# WBZ450 register map
Vendor: Microchip
Registers are 32-bit, read-write, reset 0x0 unless marked. A register's access mark holds for its fields unless they carry their own. Addresses are absolute, and some are shared; only a register's first bit layout is shown; [hi:lo] are bit positions; {n}, {i} and the like mark numbered series; 'fields as' and 'values as' point back to an identical list.

## ADCHS
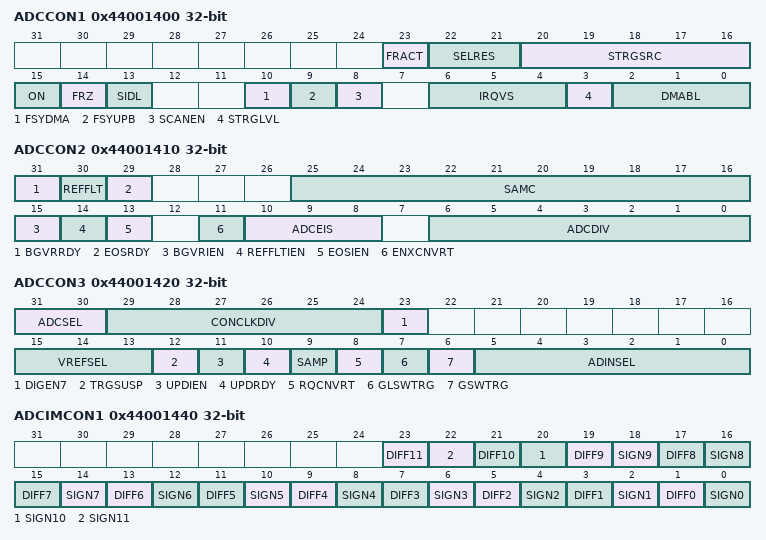
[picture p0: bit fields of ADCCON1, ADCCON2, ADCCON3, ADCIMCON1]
0x44001400 ADCCON1
  [23] FRACT — Fractional Data Output Format bit
    1=FRAC (Fractional); 0=INT (Integer)
  [22:21] SELRES — Shared ADC7 Resolution bits
    3=12_BITS (12 bits (default)); 2=10_BITS; 1=8_BITS; 0=6_BITS
  [20:16] STRGSRC — Scan Trigger Source Select bits
    31=EXT_TRIG_VAL (External trigger for validation); {v}=EVSYS_{v+31} (ADC_TRIG_{v}) (v=5..16); 4=INT0; 2=SW_LVL (Software level trigger); 1=SW_EDGE (Software edge trigger); 0=NONE (No Trigger)
  [15] ON — ADC Module Enable bit
    1=ENABLED (ADC module is enabled); 0=DISABLED (ADC module is disabled)
  [14] FRZ
  [13] SIDL — Stop in Idle Mode bit
    1=DISCONTINUE (Discontinue module operation when device enters Idle mode); 0=CONTINUE (Continue module operation in Idle mode)
  [10] FSYDMA
  [9] FSYUPB
  [8] SCANEN
  [6:4] IRQVS — Interrupt Vector Shift bits
    {v}=SHL_{v} (Shift x left {v} bit position) (v=0..7)
  [3] STRGLVL — Scan Trigger High Level/Positive Edge Sensitivity bit
    1=SCTRIG_HIGH (Scan trigger is high level sensitive. Once STRIG mode is selected the scan trigger will continue for all selected analog inputs); 0=SCTRIG_POSEDGE (Scan trigger is positive edge sensitive. Once STRIG mode is selected only a single scan trigger will be generated which will complete the scan of all selected analog inputs. (TRGSRCx in the ADCTRGx register))
  [2:0] DMABL — DMA to System RAM Buffer Length Size bits
    7=128_DMABL (Allocates 128 locations in system memory to each analog input); 6=64_DMABL (Allocates 64 locations in system memory to each analog input); 5=32_DMABL (Allocates 32 locations in system memory to each analog input); 4=16_DMABL (Allocates 16 locations in system memory to each analog input); 3=8_DMABL (Allocates 8 locations in system memory to each analog input); 2=4_DMABL (Allocates 4 locations in system memory to each analog input); 1=2_DMABL (Allocates 2 locations in system memory to each analog input); 0=1_DMABL (Allocates 1 location in system memory to each analog input)
{0x440013F4+0x10*i} ADCCON{i}CLR (i=1..3)
{0x440013F8+0x10*i} ADCCON{i}SET (i=1..3)
{0x440013FC+0x10*i} ADCCON{i}INV (i=1..3)
0x44001410 ADCCON2
  [31] BGVRRDY — Band Gap Voltage/ADC Reference Voltage Status bit
    1=VREF_RDY (Both band gap voltage and ADC reference voltages (Vref) are ready); 0=VREF_NOTRDY (Either or both band gap voltage and ADC reference voltages (Vref) are not ready)
  [30] REFFLT — Band Gap/ Vref / AVdd BOR Fault Status bit
    1=BG_VREF_FLT (Fault in band gap or the Vref voltage while the ON bit (ADCCON1) was set. Most likely a band gap or Vref fault will be caused by a BOR of the analog Vdd supply.); 0=BG_VREF_OK (Band gap and Vref voltage are working properly)
  [29] EOSRDY — End of Scan Interrupt Status bit
    1=SCAN_COMPLETE (All analog inputs are considered for scanning through the scan trigger (all analog inputs specified in the ADCCSS1 and ADCCSS2 registers) have completed scanning); 0=SCAN_NOT_COMPLETE (Scanning has not completed)
  [25:16] SAMC — Sample Time for the Shared ADC (ADC7) bits
  [15] BGVRIEN — Band Gap/ Vref Voltage Ready Interrupt Enable bit
    1=BGVRDDY_INT (Interrupt will be generated when the BGVRDDY bit is set); 0=NOBGVRDDY_INT (No interrupt is generated when the BGVRRDY bit is set)
  [14] REFFLTIEN — Band Gap/ Vref Voltage Fault Interrupt Enable bit
    1=REFFLT_INT (Interrupt will be generated when the REFFLT bit is set); 0=NOREFFLT_INT (No interrupt is generated when the REFFLT bit is set)
  [13] EOSIEN — End of Scan Interrupt Enable bit
    1=EOSRDY_INT (Interrupt will be generated when EOSRDY bit is set); 0=NOEOSRDY_INT (No interrupt is generated when the EOSRDY bit is set)
  [11] ENXCNVRT
  [10:8] ADCEIS — Shared ADC Early Interrupt Select bits
    {v}={v+1}CLKS_EARLY (The data ready interrupt is generated {v+1} ADC clocks prior to end of conversion) (v=2..7); 1=2CLKS_EARLY (The data ready interrupt is generated 2 ADC module clocks prior to end of conversion); 0=1CLKS_EARLY (The data ready interrupt is generated 1 ADC module clock prior to end of conversion)
  [6:0] ADCDIV — Shared ADC Clock Divider bits
0x44001420 ADCCON3
  [31:30] ADCSEL — Analog-to-Digital Clock Source bits
    3=SYSCLK; 2=REFCLK3; 1=FRC; 0=PBCLK1
  [29:24] CONCLKDIV — Analog-to-Digital Control Clock Divider bits
  [23] DIGEN7 — Shared ADC (ADC7) Digital Enable bit
  [15:13] VREFSEL — Voltage Reference Input Selection bits
    0=AVDD_AVSS (ADC VREFH is AVDD, ADC VREFL is AVSS)
  [12] TRGSUSP — Trigger Suspend bit
    1=TRIG_BLOCKED (Triggers are blocked from starting a new analog-to-digital conversion); 0=TRIG_NOT_BLOCKED (Triggers are not blocked)
  [11] UPDIEN — Update Ready Interrupt Enable bit
    1=INT_ON_UPDATE_RDY (Interrupt will be generated when the UPDRDY bit is set by hardware); 0=NO_INT_ON_UPDATE_RDY (No interrupt is generated)
  [10] UPDRDY — ADC Update Ready Status bit
    1=UPDATE_RDY (ADC SFRs can be updated); 0=UPDATE_NOT_RDY (ADC SFRs cannot be updated)
  [9] SAMP — Shared ADC7 Analog Input Sampling Enable bit
    1=SAMPLE (The ADC S&H amplifier is sampling); 0=HOLD (The ADC S&H amplifier is holding)
  [8] RQCNVRT — Individual ADC Input Conversion Request bit
    1=IND_TRIGGER (Trigger the conversion of the selected ADC input as specified by the ADINSEL bits); 0=NO_TRIGGER (Do not trigger the conversion)
  [7] GLSWTRG — Global Level Software Trigger bit
    1=GLSWTRG (Trigger conversion for ADC inputs that have selected the GLSWTRG bit as the trigger signal); 0=NO_GLSWTRG (Do not trigger an analog-to-digital conversion)
  [6] GSWTRG — Global Software Trigger bit
    1=GSWTRG (Trigger conversion for ADC inputs that have selected the GSWTRG bit as either through the associated TRGSRC bits in the ADCTRGx registers or through the STRGSRC<4:0> bits in the ADCCON1 register the trigger signal); 0=NO_GSWTRG (Do not trigger an analog-to-digital conversion)
  [5:0] ADINSEL — Analog Input Select bits
    11=TMP_SENSE (CTMU Temperature Sensor (internal AN11)); 10=VBATDIV2_SENSE (VBAT/2 (internal AN10)); 9=1P2V_SENSE (IVref 1.2V (internal AN9)); 8=BGREF (BandGap Reference (internal AN8)); {v}=AN{v} (v=0..7)
0x44001440 ADCIMCON1
  [23] DIFF11 — AN11 Mode bit
    1=DIFF (Selects AN11 differential input pair as AN11+ and ANN0-); 0=SINGLE (AN11 is using Single-ended mode)
  [2n] SIGN{n} (n=0..11) — AN{n} Signed Data Mode bit
    1=SIGNED (AN{n} is using Signed Data mode); 0=UNSIGNED (AN{n} is using Unsigned Data mode)
  [21] DIFF10 — AN10 Mode bit
    1=DIFF (Selects AN10 differential input pair as AN10+ and ANN0-); 0=SINGLE (AN10 is using Single-ended mode)
  [19] DIFF9 — AN9 Mode bit
    1=DIFF (Selects AN9 differential input pair as AN9+ and ANN0-); 0=SINGLE (AN9 is using Single-ended mode)
  [17] DIFF8 — AN 8 Mode bit
    1=DIFF (Selects AN8 differential input pair as AN8+ and ANN0-); 0=SINGLE (AN8 is using Single-ended mode)
  [2n+1] DIFF{n} (n=0..7) — AN{n} Mode bit
    1=DIFF (Selects AN{n} differential input pair as AN{n}+ and ANN0-); 0=SINGLE (AN{n} is using Single-ended mode)
0x44001444 ADCIMOD1CLR
0x44001448 ADCIMOD1SET
0x4400144C ADCIMOD1INV
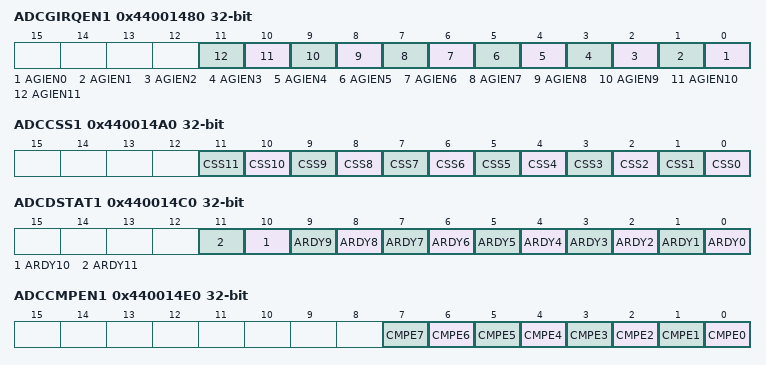
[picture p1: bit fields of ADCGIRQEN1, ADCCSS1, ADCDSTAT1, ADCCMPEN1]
0x44001480 ADCGIRQEN1
  [all] fields
    1=ENABLED (Interrupts are enabled for the selected analog input. The interrupt is generated after the converted data is ready (indicated by the AIRDYx bit of the ADCDSTAT1 register)); 0=DISABLED (Interrupts are disabled)
  [n] AGIEN{n} (n=0..11) — ADC Global Interrupt Enable bit
0x44001484 ADCGIRQEN1CLR
0x44001488 ADCGIRQEN1SET
0x4400148C ADCGIRQEN1INV
0x440014A0 ADCCSS1
  [n] CSS{n} (n=0..11) — Analog Common Scan Select bits
    1=SEL_AN{n} (Select ANx for input scan (i.e.ANx = CSSx and scan is sequential starting with the lowest to highest enabled CSSx analog input pin)); 0=SKIP_AN{n} (Skip ANx for input scan)
0x440014A4 ADCCSS1CLR
0x440014A8 ADCCSS1SET
0x440014AC ADCCSS1INV
0x440014C0 ADCDSTAT1
  [n] ARDY{n} (n=0..11)
0x440014C4 ADCDSTAT1CLR
0x440014C8 ADCDSTAT1SET
0x440014CC ADCDSTAT1INV
0x440014E0 ADCCMPEN1
  [n] CMPE{n} (n=0..7)
0x440014E4 ADCCMPEN0CLR
0x440014E8 ADCCMPEN0SET
0x440014EC ADCCMPEN0INV
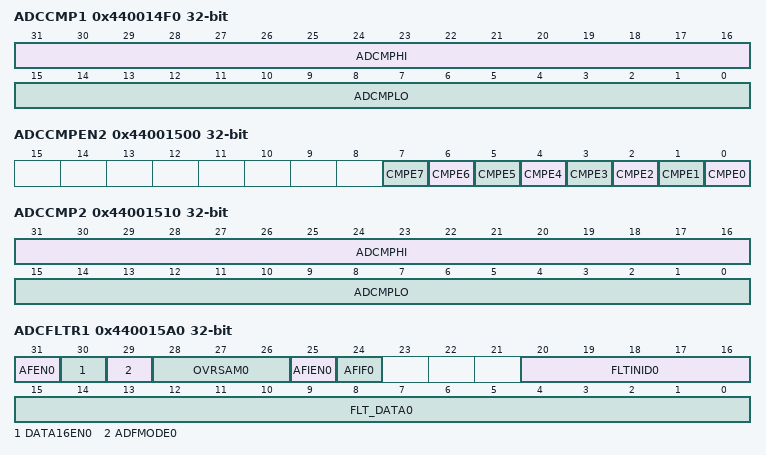
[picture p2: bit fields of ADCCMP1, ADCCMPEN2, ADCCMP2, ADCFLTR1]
0x440014F0 ADCCMP1
  [31:16] ADCMPHI, [15:0] ADCMPLO
0x440014F4 ADCCMP0CLR
0x440014F8 ADCCMP0SET
0x440014FC ADCCMP0INV
0x44001500 ADCCMPEN2
  [n] CMPE{n} (n=0..7)
0x44001504 ADCCMPEN1CLR
0x44001508 ADCCMPEN1SET
0x4400150C ADCCMPEN1INV
0x44001510 ADCCMP2
  [31:16] ADCMPHI, [15:0] ADCMPLO
0x44001514 ADDCMP1CLR
0x44001518 ADDCMP1SET
0x4400151C ADDCMP1INV
0x440015A0 ADCFLTR1
  [31] AFEN0, [30] DATA16EN0, [29] ADFMODE0, [28:26] OVRSAM0, [25] AFIEN0, [24] AFIF0, [20:16] FLTINID0, [15:0] FLT_DATA0
0x440015A4 ADCFLTR0CLR
0x440015A8 ADCFLTR0SET
0x440015AC ADCFLTR0INV
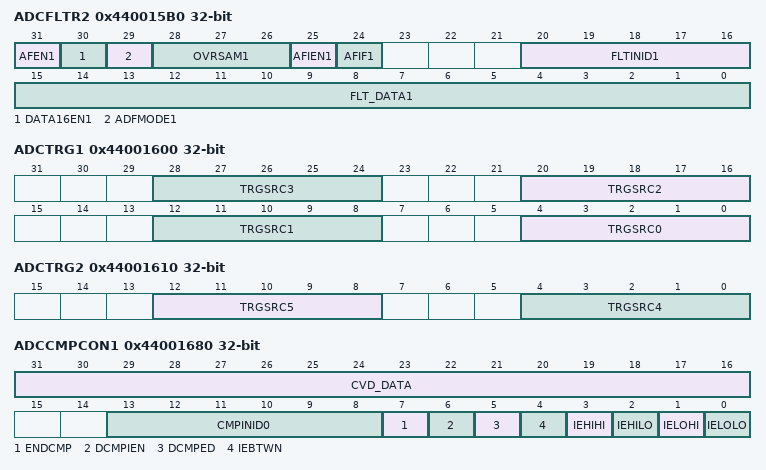
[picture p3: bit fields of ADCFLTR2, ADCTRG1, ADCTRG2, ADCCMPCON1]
0x440015B0 ADCFLTR2
  [31] AFEN1, [30] DATA16EN1, [29] ADFMODE1, [28:26] OVRSAM1, [25] AFIEN1, [24] AFIF1, [20:16] FLTINID1, [15:0] FLT_DATA1
0x440015B4 ADCFLTR1CLR
0x440015B8 ADCFLTR1SET
0x440015BC ADCFLTR1INV
0x44001600 ADCTRG1
  [all] fields
    {v}=EVSYS_{v+31} (ADC_TRIG_{v}) (v=5..16); 4=INT0; 3=SCAN_TRIG (Scan trigger); 2=SW_LVL (Software level trigger); 1=SW_EDGE (Software edge trigger); 0=NONE (No Trigger)
  [8n+4:8n] TRGSRC{n} (n=0..3) — Trigger Source for Conversion of ADC{n} Module Select bits
0x44001604 ADCTRG1CLR
0x44001608 ADCTRG1SET
0x4400160C ADCTRG1INV
0x44001610 ADCTRG2
  [12:8] TRGSRC5 — Trigger Source for Conversion of ADC5 Module Select bits
    values as the fields of ADCTRG1
  [4:0] TRGSRC4 — Trigger Source for Conversion of ADC4 Module Select bits
    values as the fields of ADCTRG1
0x44001614 ADTRG2CLR
0x44001618 ADTRG2SET
0x4400161C ADTRG2INV
0x44001624 ADTRG3CLR
0x44001628 ADTRG3SET
0x4400162C ADTRG3INV
0x44001680 ADCCMPCON1
  [31:16] CVD_DATA, [13:8] CMPINID0, [7] ENDCMP, [6] DCMPIEN, [5] DCMPED, [4] IEBTWN, [3] IEHIHI, [2] IEHILO, [1] IELOHI, [0] IELOLO
0x44001684 ADCCMPCON1CLR
0x44001688 ADCCMPCON1SET
0x4400168C ADCCMPCON1INV
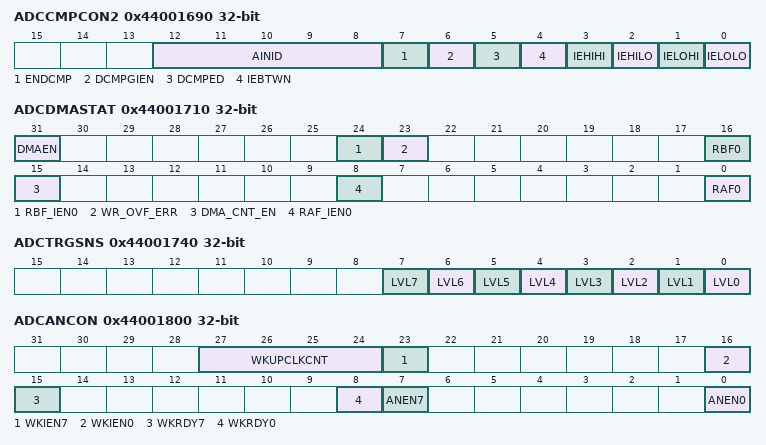
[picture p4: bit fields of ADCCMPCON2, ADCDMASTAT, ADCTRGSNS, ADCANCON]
0x44001690 ADCCMPCON2
  [12:8] AINID, [7] ENDCMP, [6] DCMPGIEN, [5] DCMPED, [4] IEBTWN, [3] IEHIHI, [2] IEHILO, [1] IELOHI, [0] IELOLO
0x44001694 ADCMPCON2CLR
0x44001698 ADCMPCON2SET
0x4400169C ADCMPCON2INV
0x440016E4 ADCFSTATCLR
0x440016E8 ADCFSTATSET
0x440016EC ADCFSTATINV
0x440016F4 ADCFIFOCLR
0x440016F8 ADCFIFOSET
0x440016FC ADCFIFOINV
0x44001700 ADCBASE
  [15:0] ADCBASE
0x44001704 ADCBASECLR
0x44001708 ADCBASESET
0x4400170C ADCBASEINV
0x44001710 ADCDMASTAT
  [31] DMAEN, [24] RBF_IEN0, [23] WR_OVF_ERR, [16] RBF0, [15] DMA_CNT_EN, [8] RAF_IEN0, [0] RAF0
0x44001714 ADCDMASTATCLR
0x44001718 ADCDMASTATSET
0x4400171C ADCDMASTATINV
0x44001720 ADCCNTB
0x44001724 ADCCNTBCLR
0x44001728 ADCCNTBSET
0x4400172C ADCCNTBINV
0x44001730 ADCDMAB
  [31:0] ADDMAB
0x44001734 ADCDMABCLR
0x44001738 ADCDMABSET
0x4400173C ADCDMABINV
0x44001740 ADCTRGSNS
  [n] LVL{n} (n=0..7)
0x44001744 ADCTRGSNSCLR
0x44001748 ADCTRGSNSSET
0x4400174C ADCTRGSNSINV
0x44001754 ADC0TIMECLR
0x44001758 ADC0TIMESET
0x4400175C ADC0TIMEINV
0x440017E4 ADCEISTAT1CLR
0x440017E8 ADCEISTAT1SET
0x440017EC ADCEISTAT1INV
0x44001800 ADCANCON
  [27:24] WKUPCLKCNT, [23] WKIEN7, [16] WKIEN0, [15] WKRDY7, [8] WKRDY0, [7] ANEN7, [0] ANEN0
0x44001804 ADCANLCTLCLR
0x44001808 ADCANLCTLSET
0x4400180C ADCANLCTLINV
0x44001A70 ADC7CFG
0x44001A74 ADCFGSHRCLR
0x44001A78 ADCFGSHRSET
0x44001A7C ADCFGSHRINV
0x44001A84 ADCSVCONCLR
0x44001A88 ADCSVCONSET
0x44001A8C ADCSVCONINV
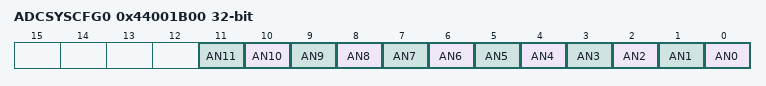
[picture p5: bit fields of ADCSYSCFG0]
0x44001B00 ADCSYSCFG0
  [n] AN{n} (n=0..11)
0x44001B04 ADCSYSCFG0CLR
0x44001B08 ADCSYSCFG0SET
0x44001B0C ADCSYSCFG0INV
{0x44001E00+0x10*i} ADCDATA{i} (i=0..11)
  [31:0] DATA
